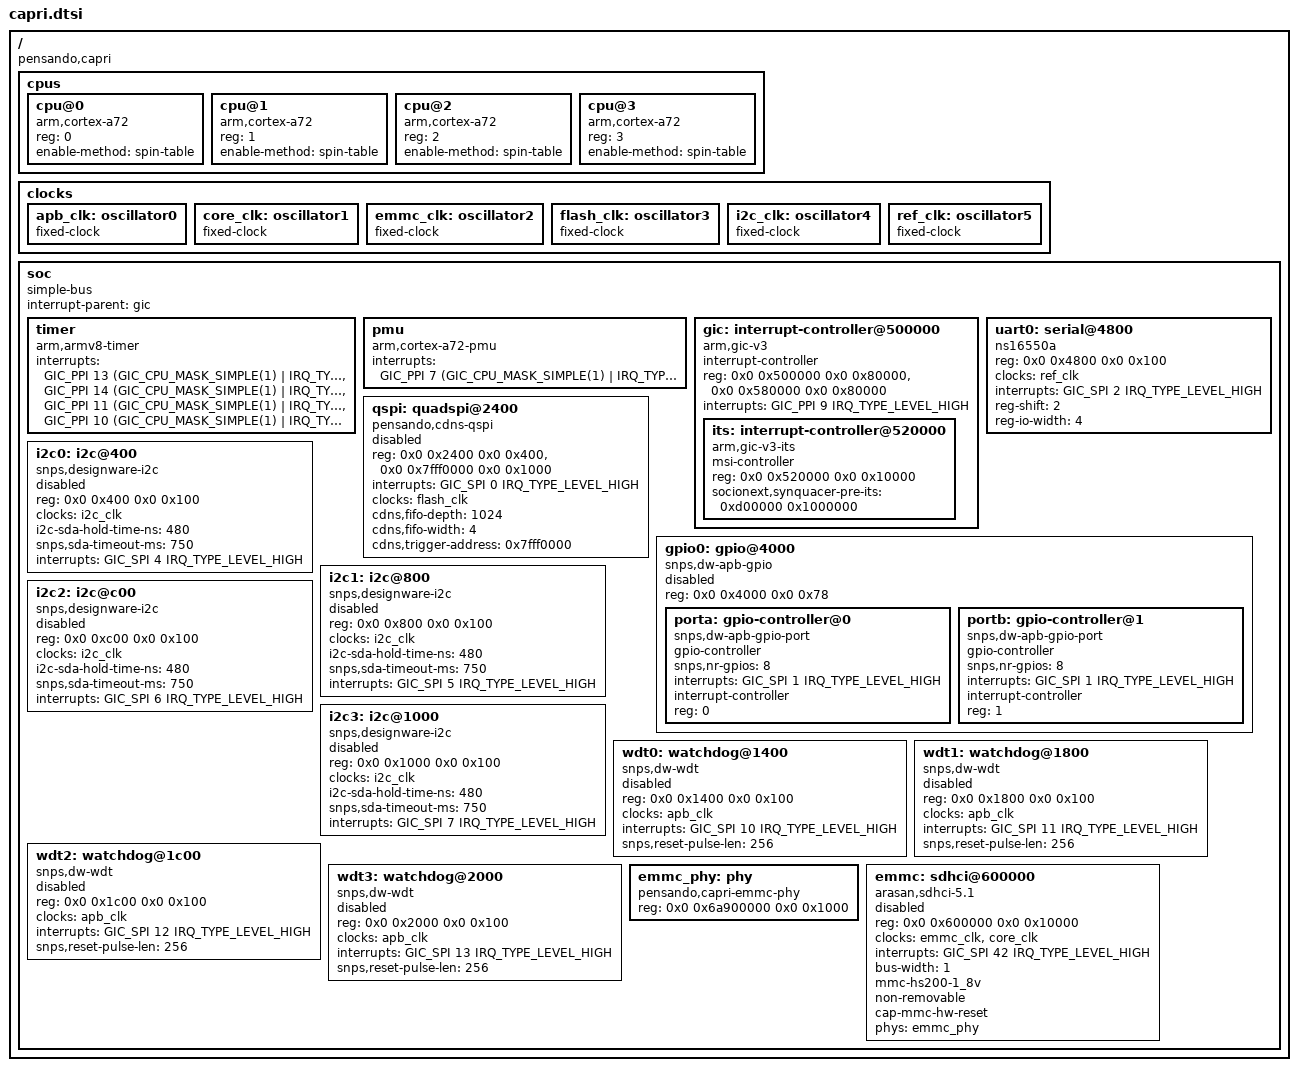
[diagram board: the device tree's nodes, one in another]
/*
 * Copyright (C) 2019 Pensando, Inc.
 *
 * This program is free software; you can redistribute it and/or modify
 * it under the terms of the GNU General Public License version 2 as
 * published by the Free Software Foundation.
 */
#include "dt-bindings/interrupt-controller/arm-gic.h"

/ {
	compatible = "pensando,capri";
	#address-cells = <2>;
	#size-cells = <2>;

	cpus {
		#address-cells = <1>;
		#size-cells = <0>;

		cpu@0 {
			device_type = "cpu";
			compatible = "arm,cortex-a72", "arm,armv8";
			reg = <0>;
			enable-method = "spin-table";
		};
		cpu@1 {
			device_type = "cpu";
			compatible = "arm,cortex-a72", "arm,armv8";
			reg = <1>;
			enable-method = "spin-table";
		};
		cpu@2 {
			device_type = "cpu";
			compatible = "arm,cortex-a72", "arm,armv8";
			reg = <2>;
			enable-method = "spin-table";
		};
		cpu@3 {
			device_type = "cpu";
			compatible = "arm,cortex-a72", "arm,armv8";
			reg = <3>;
			enable-method = "spin-table";
		};
	};

	clocks {
		apb_clk: oscillator0 {
			compatible = "fixed-clock";
			#clock-cells = <0>;
		};
		core_clk: oscillator1 {
			compatible = "fixed-clock";
			#clock-cells = <0>;
		};
		emmc_clk: oscillator2 {
			compatible = "fixed-clock";
			#clock-cells = <0>;
		};
		flash_clk: oscillator3 {
			compatible = "fixed-clock";
			#clock-cells = <0>;
		};
		i2c_clk: oscillator4 {
			compatible = "fixed-clock";
			#clock-cells = <0>;
		};
		ref_clk: oscillator5 {
			compatible = "fixed-clock";
			#clock-cells = <0>;
		};
	};

	soc {
		compatible = "simple-bus";
		#address-cells = <2>;
		#size-cells = <2>;
		ranges;
		interrupt-parent = <&gic>;

		timer {
			compatible = "arm,armv8-timer";
			interrupts = <GIC_PPI 13 (GIC_CPU_MASK_SIMPLE(1) |
						IRQ_TYPE_LEVEL_LOW)>,
				     <GIC_PPI 14 (GIC_CPU_MASK_SIMPLE(1) |
						IRQ_TYPE_LEVEL_LOW)>,
				     <GIC_PPI 11 (GIC_CPU_MASK_SIMPLE(1) |
						IRQ_TYPE_LEVEL_LOW)>,
				     <GIC_PPI 10 (GIC_CPU_MASK_SIMPLE(1) |
						IRQ_TYPE_LEVEL_LOW)>;
		};

		pmu {
			compatible = "arm,cortex-a72-pmu";
			interrupts = <GIC_PPI 7 (GIC_CPU_MASK_SIMPLE(1) |
					IRQ_TYPE_LEVEL_LOW)>;
		};

		gic: interrupt-controller@500000 {
			compatible = "arm,gic-v3";
			#interrupt-cells = <3>;
			#address-cells = <2>;
			#size-cells = <2>;
			ranges;
			interrupt-controller;
			reg = <0x0 0x500000 0x0 0x80000>,	// GICD
			      <0x0 0x580000 0x0 0x80000>;	// GICR
			interrupts = <GIC_PPI 9 IRQ_TYPE_LEVEL_HIGH>;

			its: interrupt-controller@520000 {
				compatible = "arm,gic-v3-its";
				msi-controller;
				#msi-cells = <1>;
				reg = <0x0 0x520000 0x0 0x10000>;
				socionext,synquacer-pre-its =
							<0xd00000 0x1000000>;
			};
		};

		uart0: serial@4800 {
			device_type = "serial";
			compatible = "ns16550a";
			reg = <0x0 0x4800 0x0 0x100>;
			clocks = <&ref_clk>;
			interrupts = <GIC_SPI 2 IRQ_TYPE_LEVEL_HIGH>;
			reg-shift = <2>;
			reg-io-width = <4>;
		};

		qspi: quadspi@2400 {
			compatible = "pensando,cdns-qspi";
			#address-cells = <1>;
			#size-cells = <0>;
			reg = <0x0 0x2400 0x0 0x400>,
			      <0x0 0x7fff0000 0x0 0x1000>;
			interrupts = <GIC_SPI 0 IRQ_TYPE_LEVEL_HIGH>;
			clocks = <&flash_clk>;
			cdns,fifo-depth = <1024>;
			cdns,fifo-width = <4>;
			cdns,trigger-address = <0x7fff0000>;
			status = "disabled";
		};

		gpio0: gpio@4000 {
			#address-cells = <1>;
			#size-cells = <0>;
			compatible = "snps,dw-apb-gpio";
			reg = <0x0 0x4000 0x0 0x78>;
			status = "disabled";

			porta: gpio-controller@0 {
				compatible = "snps,dw-apb-gpio-port";
				gpio-controller;
				#gpio-cells = <2>;
				snps,nr-gpios = <8>;
				interrupts = <GIC_SPI 1 IRQ_TYPE_LEVEL_HIGH>;
				interrupt-controller;
				reg = <0>;
			};
			portb: gpio-controller@1 {
				compatible = "snps,dw-apb-gpio-port";
				gpio-controller;
				#gpio-cells = <2>;
				snps,nr-gpios = <8>;
				interrupts = <GIC_SPI 1 IRQ_TYPE_LEVEL_HIGH>;
				interrupt-controller;
				reg = <1>;
			};
		};

		i2c0: i2c@400 {
			compatible = "snps,designware-i2c";
			reg = <0x0 0x400 0x0 0x100>;
			clocks = <&i2c_clk>;
			#address-cells = <1>;
			#size-cells = <0>;
			i2c-sda-hold-time-ns = <480>;
			snps,sda-timeout-ms = <750>;
			interrupts = <GIC_SPI 4 IRQ_TYPE_LEVEL_HIGH>;
			status = "disabled";
		};
		i2c1: i2c@800 {
			compatible = "snps,designware-i2c";
			reg = <0x0 0x800 0x0 0x100>;
			clocks = <&i2c_clk>;
			#address-cells = <1>;
			i2c-sda-hold-time-ns = <480>;
			snps,sda-timeout-ms = <750>;
			interrupts = <GIC_SPI 5 IRQ_TYPE_LEVEL_HIGH>;
			#size-cells = <0>;
			status = "disabled";
		};
		i2c2: i2c@c00 {
			compatible = "snps,designware-i2c";
			reg = <0x0 0xc00 0x0 0x100>;
			clocks = <&i2c_clk>;
			#address-cells = <1>;
			#size-cells = <0>;
			i2c-sda-hold-time-ns = <480>;
			snps,sda-timeout-ms = <750>;
			interrupts = <GIC_SPI 6 IRQ_TYPE_LEVEL_HIGH>;
			status = "disabled";
		};
		i2c3: i2c@1000 {
			compatible = "snps,designware-i2c";
			reg = <0x0 0x1000 0x0 0x100>;
			clocks = <&i2c_clk>;
			#address-cells = <1>;
			#size-cells = <0>;
			i2c-sda-hold-time-ns = <480>;
			snps,sda-timeout-ms = <750>;
			interrupts = <GIC_SPI 7 IRQ_TYPE_LEVEL_HIGH>;
			status = "disabled";
		};

		wdt0: watchdog@1400 {
			compatible = "snps,dw-wdt";
			reg = <0x0 0x1400 0x0 0x100>;
			clocks = <&apb_clk>;
			interrupts = <GIC_SPI 10 IRQ_TYPE_LEVEL_HIGH>;
			snps,reset-pulse-len = <256>;
			status = "disabled";
		};
		wdt1: watchdog@1800 {
			compatible = "snps,dw-wdt";
			reg = <0x0 0x1800 0x0 0x100>;
			clocks = <&apb_clk>;
			interrupts = <GIC_SPI 11 IRQ_TYPE_LEVEL_HIGH>;
			snps,reset-pulse-len = <256>;
			status = "disabled";
		};
		wdt2: watchdog@1c00 {
			compatible = "snps,dw-wdt";
			reg = <0x0 0x1c00 0x0 0x100>;
			clocks = <&apb_clk>;
			interrupts = <GIC_SPI 12 IRQ_TYPE_LEVEL_HIGH>;
			snps,reset-pulse-len = <256>;
			status = "disabled";
		};
		wdt3: watchdog@2000 {
			compatible = "snps,dw-wdt";
			reg = <0x0 0x2000 0x0 0x100>;
			clocks = <&apb_clk>;
			interrupts = <GIC_SPI 13 IRQ_TYPE_LEVEL_HIGH>;
			snps,reset-pulse-len = <256>;
			status = "disabled";
		};

		emmc_phy: phy {
			compatible = "pensando,capri-emmc-phy";
			reg = <0x0 0x6a900000 0x0 0x1000>;
			#phy-cells = <0>;
		};
		emmc: sdhci@600000 {
			compatible = "arasan,sdhci-5.1";
			reg = <0x0 0x600000 0x0 0x10000>;
			clock-names = "clk_xin", "clk_ahb";
			clocks = <&emmc_clk>, <&core_clk>;
			interrupts = <GIC_SPI 42 IRQ_TYPE_LEVEL_HIGH>;
			bus-width = <1>;
			mmc-hs200-1_8v;
			non-removable;
			cap-mmc-hw-reset;
			phys = <&emmc_phy>;
			phy-names = "phy_arasan";
			status = "disabled";
		};
	};
};
